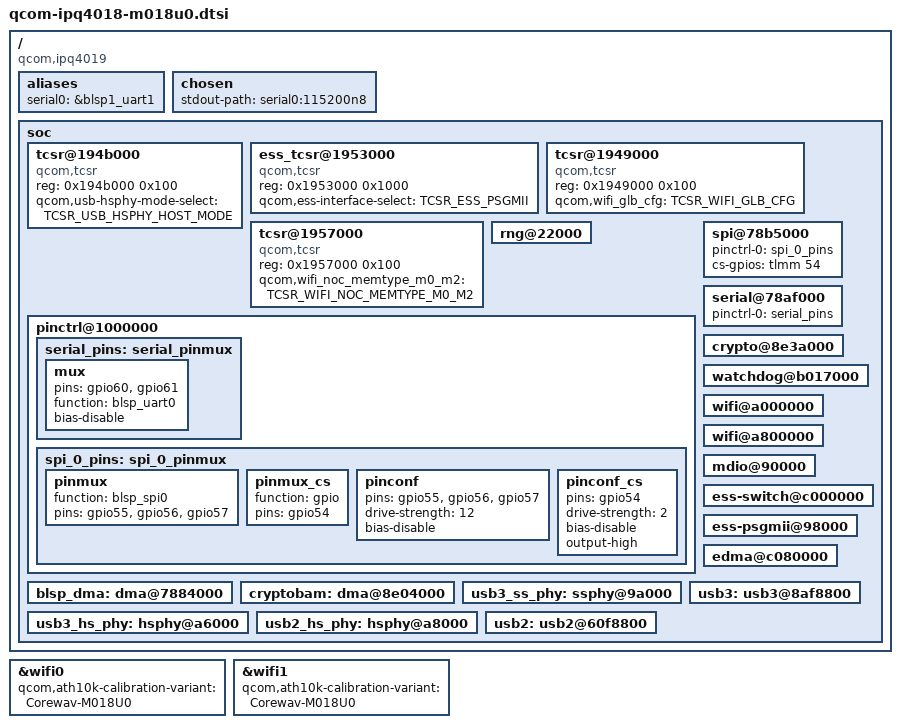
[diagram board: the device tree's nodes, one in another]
// SPDX-License-Identifier: GPL-2.0-or-later OR MIT

#include "qcom-ipq4019.dtsi"
#include <dt-bindings/gpio/gpio.h>
#include <dt-bindings/input/input.h>
#include <dt-bindings/soc/qcom,tcsr.h>

/ {
	compatible = "qcom,ipq4019";

	aliases {
		serial0 = &blsp1_uart1;
	};

	chosen {
		stdout-path = "serial0:115200n8";
	};

	soc {
		tcsr@194b000 {
			/* select hostmode */
			compatible = "qcom,tcsr";
			reg = <0x194b000 0x100>;
			qcom,usb-hsphy-mode-select = <TCSR_USB_HSPHY_HOST_MODE>;
			status = "okay";
		};

		ess_tcsr@1953000 {
			compatible = "qcom,tcsr";
			reg = <0x1953000 0x1000>;
			qcom,ess-interface-select = <TCSR_ESS_PSGMII>;
		};

		tcsr@1949000 {
			compatible = "qcom,tcsr";
			reg = <0x1949000 0x100>;
			qcom,wifi_glb_cfg = <TCSR_WIFI_GLB_CFG>;
		};

		tcsr@1957000 {
			compatible = "qcom,tcsr";
			reg = <0x1957000 0x100>;
			qcom,wifi_noc_memtype_m0_m2 = <TCSR_WIFI_NOC_MEMTYPE_M0_M2>;
		};

		rng@22000 {
			status = "okay";
		};

		pinctrl@1000000 {
			serial_pins: serial_pinmux {
				mux {
					pins = "gpio60", "gpio61";
					function = "blsp_uart0";
					bias-disable;
				};
			};

			spi_0_pins: spi_0_pinmux {
				pinmux {
					function = "blsp_spi0";
					pins = "gpio55", "gpio56", "gpio57";
				};

				pinmux_cs {
					function = "gpio";
					pins = "gpio54";
				};

				pinconf {
					pins = "gpio55", "gpio56", "gpio57";
					drive-strength = <12>;
					bias-disable;
				};

				pinconf_cs {
					pins = "gpio54";
					drive-strength = <2>;
					bias-disable;
					output-high;
				};
			};
		};

		blsp_dma: dma@7884000 {
			status = "okay";
		};

		spi@78b5000 {
			pinctrl-0 = <&spi_0_pins>;
			pinctrl-names = "default";
			status = "okay";
			cs-gpios = <&tlmm 54 0>;
		};

		serial@78af000 {
			pinctrl-0 = <&serial_pins>;
			pinctrl-names = "default";
			status = "okay";
		};

		cryptobam: dma@8e04000 {
			status = "okay";
		};

		crypto@8e3a000 {
			status = "okay";
		};

		watchdog@b017000 {
			status = "okay";
		};

		wifi@a000000 {
			status = "okay";
		};

		wifi@a800000 {
			status = "okay";
		};

		mdio@90000 {
			status = "okay";
		};

		ess-switch@c000000 {
			status = "okay";
		};

		ess-psgmii@98000 {
			status = "okay";
		};

		edma@c080000 {
			status = "okay";
		};

		usb3_ss_phy: ssphy@9a000 {
			status = "okay";
		};

		usb3_hs_phy: hsphy@a6000 {
			status = "okay";
		};

		usb3: usb3@8af8800 {
			status = "okay";
		};

		usb2_hs_phy: hsphy@a8000 {
			status = "okay";
		};

		usb2: usb2@60f8800 {
			status = "okay";
		};
	};
};

&wifi0 {
	status = "okay";
	qcom,ath10k-calibration-variant = "Corewav-M018U0";
};

&wifi1 {
	status = "okay";
	qcom,ath10k-calibration-variant = "Corewav-M018U0";
};
